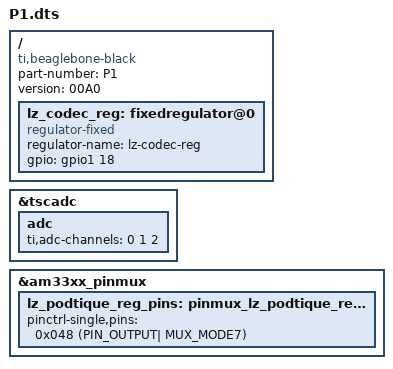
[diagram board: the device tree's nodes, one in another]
#define PULL_DISABLE		(1 << 3)
#define PIN_OUTPUT		(PULL_DISABLE)
#define MUX_MODE0	0
#define MUX_MODE1	1
#define MUX_MODE2	2
#define MUX_MODE3	3
#define MUX_MODE4	4
#define MUX_MODE5	5
#define MUX_MODE6	6
#define MUX_MODE7	7
#define GPIO_ACTIVE_HIGH 0
#define GPIO_ACTIVE_LOW 1


/dts-v1/;
/plugin/;

/ {
    compatible = "ti,beaglebone-black";

    /* identification */
    part-number = "P1";

    /* version */
    version = "00A0";

	lz_codec_reg: fixedregulator@0 {
		compatible = "regulator-fixed";
		regulator-name = "lz-codec-reg";
		gpio = <&gpio1 18 GPIO_ACTIVE_HIGH>;
	};
	
	fragment@0 {
		target = <&tscadc>;
		__overlay__ {

			status = "okay";
			adc {
				ti,adc-channels = <0 1 2>;
			};
		};
	};
	
	fragment@1 {
		target = <&am33xx_pinmux>;
		__overlay__ {

			lz_podtique_reg_pins: pinmux_lz_podtique_reg_pins {
				pinctrl-single,pins = <
					0x048 (PIN_OUTPUT| MUX_MODE7)				//	CODEC regulator enable
				>;
			};
		};
	};

};
